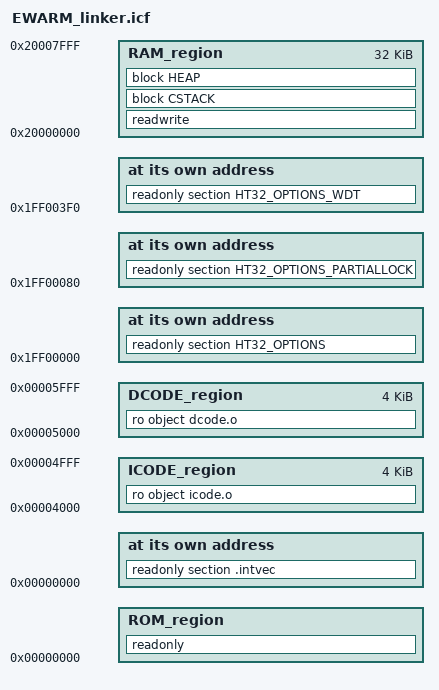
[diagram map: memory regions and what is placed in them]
/*###ICF### Section handled by ICF editor, don't touch! ****/
/*-Editor annotation file-*/
/* IcfEditorFile="$TOOLKIT_DIR$\config\ide\IcfEditor\cortex_v1_0.xml" */
/*-Specials-*/
define symbol __ICFEDIT_intvec_start__ = 0x00000000;
/*-Memory Regions-*/
define symbol __ICFEDIT_region_ROM_start__ = 0x00000000;
define symbol __ICFEDIT_region_ROM_end__   = 0x0003FBFF;
define symbol __ICFEDIT_region_RAM_start__ = 0x20000000;
define symbol __ICFEDIT_region_RAM_end__   = 0x20007FFF;

/*Partial Lock ICODE area*/
define symbol __ICFEDIT_region_ICODE_start__ = 0x00004000;
define symbol __ICFEDIT_region_ICODE_end__   = 0x00004FFF;

/*Partial Lock DCODE area*/
define symbol __ICFEDIT_region_DCODE_start__ = 0x00005000;
define symbol __ICFEDIT_region_DCODE_end__   = 0x00005FFF;

/*-Sizes-*/
define symbol __ICFEDIT_size_cstack__ = 0x200;
define symbol __ICFEDIT_size_heap__   = 0x0;
/**** End of ICF editor section. ###ICF###*/

define memory mem with size = 4G;
define region ROM_region   = mem:[from __ICFEDIT_region_ROM_start__ to __ICFEDIT_region_ROM_end__]
                             -mem:[from __ICFEDIT_region_ICODE_start__ to __ICFEDIT_region_ICODE_end__]
                             -mem:[from __ICFEDIT_region_DCODE_start__ to __ICFEDIT_region_DCODE_end__];
define region ICODE_region = mem:[from __ICFEDIT_region_ICODE_start__ to __ICFEDIT_region_ICODE_end__];
define region DCODE_region = mem:[from __ICFEDIT_region_DCODE_start__ to __ICFEDIT_region_DCODE_end__];

define region RAM_region   = mem:[from __ICFEDIT_region_RAM_start__ to __ICFEDIT_region_RAM_end__];

define block CSTACK    with alignment = 8, size = __ICFEDIT_size_cstack__   { };
define block HEAP      with alignment = 8, size = __ICFEDIT_size_heap__     { };

initialize by copy { readwrite };
do not initialize  { section .noinit };

place at address mem:__ICFEDIT_intvec_start__ { readonly section .intvec };

/* Place ICODE Code in ICODE area  */
place in ICODE_region   { ro object icode.o };

/* Place DCODE DATA in DCODE area  */
place in DCODE_region   { ro object dcode.o };

place in ROM_region   { readonly };
place in RAM_region   { readwrite, block CSTACK, block HEAP };

define symbol op_rom_start       = 0x1FF00000;
define symbol op_wdt_start       = 0x1FF003F0;
define symbol op_pl_start        = 0x1FF00080;
place at address mem:op_rom_start   { readonly section HT32_OPTIONS };
place at address mem:op_wdt_start   { readonly section HT32_OPTIONS_WDT };
place at address mem:op_pl_start    { readonly section HT32_OPTIONS_PARTIALLOCK };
